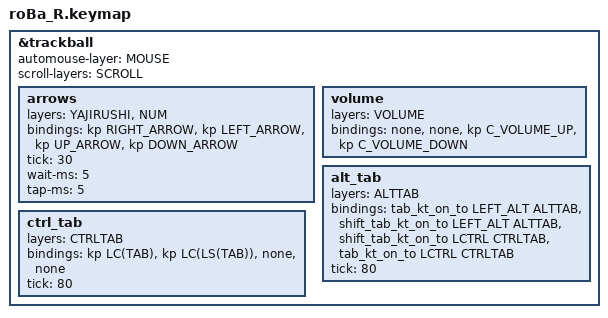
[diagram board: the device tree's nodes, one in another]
#include "roBa_L.keymap"
#include "boards/shields/Test/roBa_R.overlay"

&trackball {
    automouse-layer = <MOUSE>;
    scroll-layers = <SCROLL>;

    // snipe-layers = <3>;

    arrows {
        layers = <YAJIRUSHI>, <NUM>;
        bindings =
            <&kp RIGHT_ARROW>,
            <&kp LEFT_ARROW>,
            <&kp UP_ARROW>,
            <&kp DOWN_ARROW>;

        tick = <30>;
        wait-ms = <5>;
        tap-ms = <5>;
    };

    volume {
        layers = <VOLUME>;
        bindings = <&none>, <&none>, <&kp C_VOLUME_UP>, <&kp C_VOLUME_DOWN>;
    };

    alt_tab {
        layers = <ALTTAB>;
        bindings =
            <&tab_kt_on_to LEFT_ALT ALTTAB>,
            <&shift_tab_kt_on_to LEFT_ALT ALTTAB>,
            <&shift_tab_kt_on_to LCTRL CTRLTAB>,
            <&tab_kt_on_to LCTRL CTRLTAB>;


        tick = <80>;
    };

    ctrl_tab {
        layers = <CTRLTAB>;
        bindings = <&kp LC(TAB)>, <&kp LC(LS(TAB))>, <&none>, <&none>;

        tick = <80>;
    };
};
